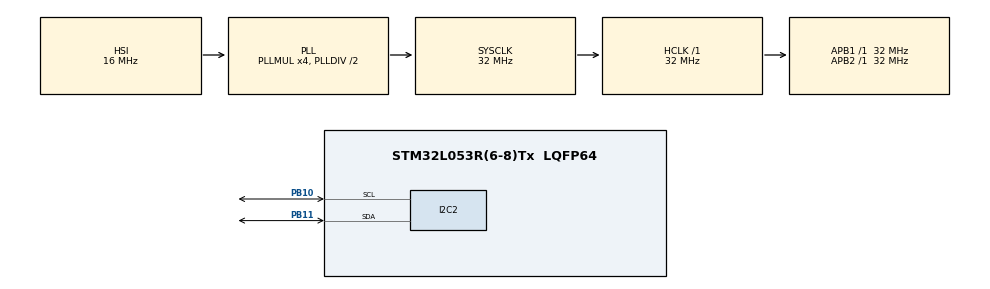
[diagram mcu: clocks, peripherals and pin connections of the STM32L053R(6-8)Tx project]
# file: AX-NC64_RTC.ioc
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I2C2.Speed=10
I2C2.Timing=0x6010C7FF
Mcu.Family=STM32L0
Mcu.Name=STM32L053R(6-8)Tx
Mcu.Package=LQFP64
PB10.Mode=I2C
PB10.Signal=I2C2_SCL
PB11.Mode=I2C
PB11.Signal=I2C2_SDA
ProjectManager.HeapSize=0x200
ProjectManager.StackSize=0x400
ProjectManager.TargetToolchain=MDK-ARM V5
RCC.AHBFreq_Value=32000000
RCC.APB1Freq_Value=32000000
RCC.APB1TimFreq_Value=32000000
RCC.APB2Freq_Value=32000000
RCC.APB2TimFreq_Value=32000000
RCC.HCLKFreq_Value=32000000
RCC.HSE_VALUE=8000000
RCC.HSI16_VALUE=16000000
RCC.HSI48_VALUE=48000000
RCC.HSI_VALUE=16000000
RCC.LSE_VALUE=32768
RCC.MSI_VALUE=2097000
RCC.PLLMUL=RCC_PLLMUL_4
RCC.SYSCLKFreq_VALUE=32000000
RCC.SYSCLKSource=RCC_SYSCLKSOURCE_PLLCLK
RCC.VCOOutputFreq_Value=64000000
board=custom

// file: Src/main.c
/* USER CODE BEGIN Header */
/**
  ******************************************************************************
  * @file           : main.c
  * @brief          : Main program body
  ******************************************************************************
  * @attention
  *
  * <h2><center>&copy; Copyright (c) 2019 STMicroelectronics.
  * All rights reserved.</center></h2>
  *
  * This software component is licensed by ST under BSD 3-Clause license,
  * the "License"; You may not use this file except in compliance with the
  * License. You may obtain a copy of the License at:
  *                        opensource.org/licenses/BSD-3-Clause
  *
  ******************************************************************************
  */
/* USER CODE END Header */

#include "main.h"

/* USER CODE BEGIN PTD */
#define DS1307_ADDR (0x68<<1)
/* USER CODE END PTD */

I2C_HandleTypeDef hi2c2;

void SystemClock_Config(void);
static void MX_GPIO_Init(void);
static void MX_I2C2_Init(void);

/* USER CODE BEGIN 0 */
uint8_t bcd2dec(uint8_t num) {
  return ((num/16 * 10) + (num % 16));
}

uint8_t read_time(uint8_t *hour, uint8_t *min, uint8_t *sec, uint8_t *date, uint8_t *month, uint8_t *year) {
	uint8_t buff[7];

	// Set address to read
	buff[0] = 0x0; // read start at address 0x0
	if (HAL_I2C_Master_Transmit(&hi2c2, DS1307_ADDR, buff, 1, 1000) == HAL_ERROR) {
		// Fail !, Write error !
		return 0;
	}

	HAL_Delay(1);

	// Read 7 bytes
	if (HAL_I2C_Master_Receive(&hi2c2, DS1307_ADDR, buff, 7, 1000) == HAL_ERROR) {
		// Fail !, read error !
		return 0;
	}

	*sec = bcd2dec(buff[0] & 0x7f);
	*min = bcd2dec(buff[1]);
	*hour = bcd2dec(buff[2] & 0x3f);
	*date = bcd2dec(buff[4]);
	*month = bcd2dec(buff[5]);
	*year = bcd2dec(buff[6]);

	return 1;
}

uint8_t h, m, s, dd, mm, yy;
/* USER CODE END 0 */

int main(void)
{

  /* MCU Configuration--------------------------------------------------------*/

  /* Reset of all peripherals, Initializes the Flash interface and the Systick. */
  HAL_Init();

  /* Configure the system clock */
  SystemClock_Config();

  /* Initialize all configured peripherals */
  MX_GPIO_Init();
  MX_I2C2_Init();

  /* Infinite loop */
  /* USER CODE BEGIN WHILE */
  while (1)
  {
		if (read_time(&h, &m, &s, &dd, &mm, &yy)) {
			// OK !
		}
		HAL_Delay(10);
    /* USER CODE END WHILE */

  }
}

void SystemClock_Config(void)
{
  RCC_OscInitTypeDef RCC_OscInitStruct = {0};
  RCC_ClkInitTypeDef RCC_ClkInitStruct = {0};

  /** Configure the main internal regulator output voltage
  */
  __HAL_PWR_VOLTAGESCALING_CONFIG(PWR_REGULATOR_VOLTAGE_SCALE1);
  /** Initializes the CPU, AHB and APB busses clocks
  */
  RCC_OscInitStruct.OscillatorType = RCC_OSCILLATORTYPE_HSI;
  RCC_OscInitStruct.HSIState = RCC_HSI_ON;
  RCC_OscInitStruct.HSICalibrationValue = RCC_HSICALIBRATION_DEFAULT;
  RCC_OscInitStruct.PLL.PLLState = RCC_PLL_ON;
  RCC_OscInitStruct.PLL.PLLSource = RCC_PLLSOURCE_HSI;
  RCC_OscInitStruct.PLL.PLLMUL = RCC_PLLMUL_4;
  RCC_OscInitStruct.PLL.PLLDIV = RCC_PLLDIV_2;
  if (HAL_RCC_OscConfig(&RCC_OscInitStruct) != HAL_OK)
  {
    Error_Handler();
  }
  /** Initializes the CPU, AHB and APB busses clocks
  */
  RCC_ClkInitStruct.ClockType = RCC_CLOCKTYPE_HCLK|RCC_CLOCKTYPE_SYSCLK
                              |RCC_CLOCKTYPE_PCLK1|RCC_CLOCKTYPE_PCLK2;
  RCC_ClkInitStruct.SYSCLKSource = RCC_SYSCLKSOURCE_PLLCLK;
  RCC_ClkInitStruct.AHBCLKDivider = RCC_SYSCLK_DIV1;
  RCC_ClkInitStruct.APB1CLKDivider = RCC_HCLK_DIV1;
  RCC_ClkInitStruct.APB2CLKDivider = RCC_HCLK_DIV1;

  if (HAL_RCC_ClockConfig(&RCC_ClkInitStruct, FLASH_LATENCY_1) != HAL_OK)
  {
    Error_Handler();
  }
}

static void MX_I2C2_Init(void)
{

  hi2c2.Instance = I2C2;
  hi2c2.Init.Timing = 0x6010C7FF;
  hi2c2.Init.OwnAddress1 = 0;
  hi2c2.Init.AddressingMode = I2C_ADDRESSINGMODE_7BIT;
  hi2c2.Init.DualAddressMode = I2C_DUALADDRESS_DISABLE;
  hi2c2.Init.OwnAddress2 = 0;
  hi2c2.Init.OwnAddress2Masks = I2C_OA2_NOMASK;
  hi2c2.Init.GeneralCallMode = I2C_GENERALCALL_DISABLE;
  hi2c2.Init.NoStretchMode = I2C_NOSTRETCH_DISABLE;
  if (HAL_I2C_Init(&hi2c2) != HAL_OK)
  {
    Error_Handler();
  }
  /** Configure Analogue filter
  */
  if (HAL_I2CEx_ConfigAnalogFilter(&hi2c2, I2C_ANALOGFILTER_ENABLE) != HAL_OK)
  {
    Error_Handler();
  }
  /** Configure Digital filter
  */
  if (HAL_I2CEx_ConfigDigitalFilter(&hi2c2, 0) != HAL_OK)
  {
    Error_Handler();
  }

}

static void MX_GPIO_Init(void)
{

  /* GPIO Ports Clock Enable */
  __HAL_RCC_GPIOB_CLK_ENABLE();

}

void Error_Handler(void)
{
}

/************************ (C) COPYRIGHT STMicroelectronics *****END OF FILE****/
